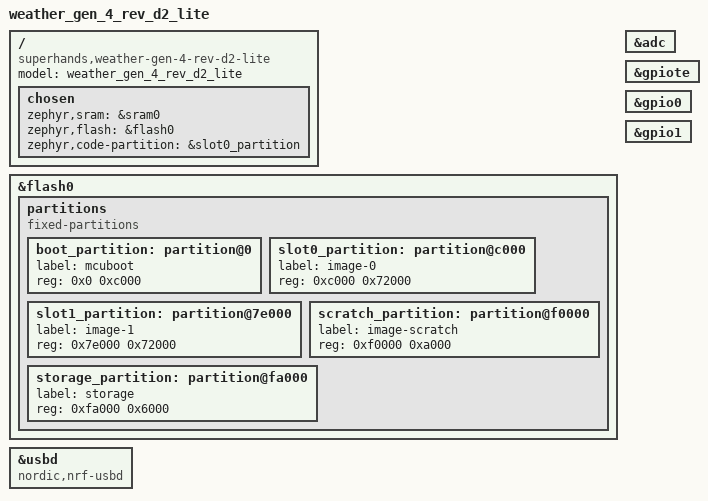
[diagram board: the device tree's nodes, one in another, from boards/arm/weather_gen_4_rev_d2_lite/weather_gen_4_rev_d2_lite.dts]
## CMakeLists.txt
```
cmake_minimum_required(VERSION 3.20.0)
find_package(Zephyr REQUIRED HINTS $ENV{ZEPHYR_BASE})

project(ble-lr-scanner)

add_subdirectory(lib/nth)

target_sources(app PRIVATE 
    src/main.cpp
    src/ble.cpp
    src/usb.cpp)
target_link_libraries(app PRIVATE nth)
target_include_directories(app PRIVATE lib/nth/inc)
```

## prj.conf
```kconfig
CONFIG_CPLUSPLUS=y
CONFIG_STD_CPP2B=y
CONFIG_LIB_CPLUSPLUS=y

CONFIG_MAIN_THREAD_PRIORITY=0
CONFIG_MAIN_STACK_SIZE=16384
CONFIG_HEAP_MEM_POOL_SIZE=8192
CONFIG_SYSTEM_WORKQUEUE_STACK_SIZE=8192
CONFIG_BT_RX_STACK_SIZE=16384
# CONFIG_LOG_PROCESS_THREAD_STACK_SIZE=16384

CONFIG_LOG=y
CONFIG_LOG_MODE_IMMEDIATE=y
CONFIG_USE_SEGGER_RTT=y
CONFIG_CONSOLE=y
CONFIG_RTT_CONSOLE=y
CONFIG_SERIAL=y
CONFIG_UART_INTERRUPT_DRIVEN=y
CONFIG_UART_LINE_CTRL=y

CONFIG_BT=y
CONFIG_BT_HCI=y
CONFIG_BT_DEBUG_LOG=y
CONFIG_BT_DEVICE_NAME="LR-Scanner"
CONFIG_BT_USER_PHY_UPDATE=y
CONFIG_BT_USER_DATA_LEN_UPDATE=y
CONFIG_BT_CTLR_PHY_CODED=y
CONFIG_BT_CTLR_DATA_LENGTH_MAX=251
CONFIG_BT_CTLR_ADV_EXT=y
# CONFIG_BT_CTLR_ADV_DATA_LEN_MAX=254
CONFIG_BT_EXT_ADV=y
CONFIG_BT_EXT_ADV_LEGACY_SUPPORT=y
CONFIG_BT_BUF_ACL_RX_SIZE=251
CONFIG_BT_BUF_ACL_TX_SIZE=251
CONFIG_BT_L2CAP_TX_MTU=247
# CONFIG_BT_MAX_CONN=2
# CONFIG_BT_MAX_PAIRED=1
# CONFIG_BT_GATT_DM=y
CONFIG_BT_GATT_CLIENT=y

# CONFIG_BT_PERIPHERAL=y
# CONFIG_BT_PERIPHERAL_PREF_MIN_INT=24
# CONFIG_BT_PERIPHERAL_PREF_MAX_INT=40
# CONFIG_BT_PERIPHERAL_PREF_LATENCY=0
# CONFIG_BT_PERIPHERAL_PREF_TIMEOUT=42
# CONFIG_BT_GAP_AUTO_UPDATE_CONN_PARAMS=n

CONFIG_BT_CENTRAL=y
CONFIG_BT_SCAN=y
CONFIG_BT_SCAN_FILTER_ENABLE=y
CONFIG_BT_SCAN_ADDRESS_CNT=1

CONFIG_REBOOT=y
CONFIG_RING_BUFFER=y
CONFIG_NEWLIB_LIBC=y
CONFIG_CBPRINTF_LIBC_SUBSTS=y
CONFIG_CBPRINTF_FP_SUPPORT=y

CONFIG_USB_DEVICE_STACK=y
CONFIG_USB_DEVICE_PRODUCT="BLE-LR Scanner"
CONFIG_USB_DEVICE_PID=0x0001
# CONFIG_USB_DEVICE_PID=0x0110
# CONFIG_USB_DEVICE_PID=0x0000
# CONFIG_USB_DEVICE_VID=0x1915
CONFIG_USB_DEVICE_INITIALIZE_AT_BOOT=n
CONFIG_USB_DEVICE_LOG_LEVEL_ERR=y
CONFIG_USB_DRIVER_LOG_LEVEL_ERR=y
CONFIG_USB_CDC_ACM=y
CONFIG_CDC_ACM_IAD=y
```

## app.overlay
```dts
/*
 * Copyright (c) 2021 Nordic Semiconductor ASA
 *
 * SPDX-License-Identifier: Apache-2.0
 */

// / {
// 	chosen {
// 		zephyr,console = &cdc_acm_uart0;
//         // zephyr,shell-uart = &cdc_acm_uart0;
// 	};
// };

&zephyr_udc0 {
	cdc_acm_uart0 {
		compatible = "zephyr,cdc-acm-uart";
	};
};
```

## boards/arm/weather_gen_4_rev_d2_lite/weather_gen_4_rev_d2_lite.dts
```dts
// Copyright (c) 2023 Nordic Semiconductor ASA
// SPDX-License-Identifier: Apache-2.0

/dts-v1/;
#include <nordic/nrf52840_qiaa.dtsi>
// #include "nrf52840dongle_nrf52840-pinctrl.dtsi"

/ {
	model = "weather_gen_4_rev_d2_lite";
	compatible = "superhands,weather-gen-4-rev-d2-lite";

	chosen {
		zephyr,sram = &sram0;
		zephyr,flash = &flash0;
		zephyr,code-partition = &slot0_partition;
		// zephyr,console = &cdc_acm_uart0;
        // zephyr,shell-uart = &cdc_acm_uart0;
	};
};

&flash0 {
	partitions {
		compatible = "fixed-partitions";
		#address-cells = <1>;
		#size-cells = <1>;

		boot_partition: partition@0 {
			label = "mcuboot";
			reg = <0x0 0xc000>;
		};
		slot0_partition: partition@c000 {
			label = "image-0";
			reg = <0xc000 0x72000>;
		};
		slot1_partition: partition@7e000 {
			label = "image-1";
			reg = <0x7e000 0x72000>;
		};
		scratch_partition: partition@f0000 {
			label = "image-scratch";
			reg = <0xf0000 0xa000>;
		};
		storage_partition: partition@fa000 {
			label = "storage";
			reg = <0xfa000 0x6000>;
		};
	};
};

&adc {
	status = "okay";
};

&gpiote {
	status = "okay";
};

&gpio0 {
	status = "okay";
};

&gpio1 {
	status = "okay";
};

// &uart0 {
// 	compatible = "nordic,nrf-uarte";
// 	status = "okay";
// 	current-speed = <115200>;
// 	// pinctrl-0 = <&uart0_default>;
// 	// pinctrl-1 = <&uart0_sleep>;
// 	// pinctrl-names = "default", "sleep";
// };

// &uart0 {
//     compatible = "zephyr,cdc-acm-uart";
//     status = "okay";
// };

zephyr_udc0: &usbd {
	compatible = "nordic,nrf-usbd";
	status = "okay";
};
```

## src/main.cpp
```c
#include <zephyr/kernel.h>
#include "ble.h"
#include "usb.h"
#include "log.h"
#include "config.h"

LOG_MODULE_REGISTER(main, LOG_LEVEL_INF);

void regout0()
{
    if ((NRF_UICR->REGOUT0 & UICR_REGOUT0_VOUT_Msk) == (UICR_REGOUT0_VOUT_DEFAULT << UICR_REGOUT0_VOUT_Pos))
    {
        NRF_NVMC->CONFIG = NVMC_CONFIG_WEN_Wen;
        while (NRF_NVMC->READY == NVMC_READY_READY_Busy) {}
        NRF_UICR->REGOUT0 = (NRF_UICR->REGOUT0 & ~((uint32_t)UICR_REGOUT0_VOUT_Msk)) | (UICR_REGOUT0_VOUT_3V0 << UICR_REGOUT0_VOUT_Pos);
        NRF_NVMC->CONFIG = NVMC_CONFIG_WEN_Ren;
        while (NRF_NVMC->READY == NVMC_READY_READY_Busy) {}
        NVIC_SystemReset();
    }
}

void approtect_hw_disable(void)
{
    if ((NRF_UICR->APPROTECT & UICR_APPROTECT_PALL_Msk) == (UICR_APPROTECT_PALL_Msk))
    {
        NRF_NVMC->CONFIG = NVMC_CONFIG_WEN_Wen << NVMC_CONFIG_WEN_Pos;
        while (NRF_NVMC->READY == NVMC_READY_READY_Busy) {}
        NRF_UICR->APPROTECT = (UICR_APPROTECT_PALL_HwDisabled << UICR_APPROTECT_PALL_Pos);
        while (NRF_NVMC->READY == NVMC_READY_READY_Busy) {}
        NRF_NVMC->CONFIG = NVMC_CONFIG_WEN_Ren << NVMC_CONFIG_WEN_Pos;
        while (NRF_NVMC->READY == NVMC_READY_READY_Busy) {}
        NVIC_SystemReset();
    }  
}

int main(void)
{
    regout0();
    approtect_hw_disable();
    app::usb_init();
#if !(USB_COBS_TEST)
    app::ble_init();
    app::ble_scan_start();
#else
    // uint8_t buf[27];
    // int cnt = 0;
    while (1) {
        // for (int i = 0; i < sizeof(buf); ++i)
        //     buf[i] = cnt * i;
        // cnt++;
        // app::usb_send(buf, sizeof(buf));
        app::usb_send("hello, world!", sizeof("hello, world!") - 1);
        app::usb_send_finalize();
        k_msleep(1000);
    }
#endif
}
```

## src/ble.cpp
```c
#include <zephyr/sys/reboot.h>
#include <zephyr/bluetooth/bluetooth.h>
#include <bluetooth/scan.h>
#include "ble.h"
#include "usb.h"
#include "log.h"
#include "config.h"

LOG_MODULE_REGISTER(ble, LOG_LEVEL_INF);

#define TRY(...)                                        \
{                                                       \
    int err = __VA_ARGS__;                              \
    if (err) {                                          \
        LOG_E("failure: " #__VA_ARGS__ " -> %d", err);  \
        return;                                         \
    }                                                   \
}

namespace app {
namespace {

struct k_work_delayable work_scan_start;
struct k_work_delayable work_scan_stop;
bool scanning = false;

constexpr auto adv_type_str(uint8_t adv_type)
{
    switch (adv_type) {
        case BT_GAP_ADV_TYPE_ADV_IND:           return "scannable and connectable";
        case BT_GAP_ADV_TYPE_ADV_DIRECT_IND:    return "directed connectable";
        case BT_GAP_ADV_TYPE_ADV_SCAN_IND:      return "non-connectable and scannable";
        case BT_GAP_ADV_TYPE_ADV_NONCONN_IND:   return "non-connectable and non-scannable";
        case BT_GAP_ADV_TYPE_SCAN_RSP:          return "additional advertising data requested by an active scanner";
        case BT_GAP_ADV_TYPE_EXT_ADV:           return "extended";
        default: return "<unknown>";
    }
}

constexpr auto phy_str(uint8_t phy)
{
    switch (phy) {
        case 0:                     return "no packets";
        case BT_GAP_LE_PHY_1M:      return "LE 1M";
        case BT_GAP_LE_PHY_2M:      return "LE 2M";
        case BT_GAP_LE_PHY_CODED:   return "LE Coded";
        default: return "<unknown>";
    }
}

void log_scan_info(struct bt_scan_device_info *info, bool connectable)
{
    char addr[BT_ADDR_LE_STR_LEN];

    bt_addr_le_to_str(info->recv_info->addr, addr, sizeof(addr));

    LOG_I("%s   \n\
        rssi:           %+d     \n\
        tx_power:       %+d     \n\
        sid:            %u      \n\
        interval:       %u ms   \n\
        adv_type:       %s      \n\
        primary_phy:    %s      \n\
        secondary_phy:  %s      \n\
        connectable:    %s",
        addr, 
        info->recv_info->rssi,
        info->recv_info->tx_power,
        info->recv_info->sid,
        info->recv_info->interval * 5 / 4,
        adv_type_str(info->recv_info->adv_type),
        phy_str(info->recv_info->primary_phy),
        phy_str(info->recv_info->secondary_phy),
        connectable ? "yes" : "no");
}

void scan_process(struct bt_scan_device_info *device_info)
{
    uint8_t* raw_data   = device_info->adv_data->data;
    uint16_t raw_len    = device_info->adv_data->len;
    LOG_HEX_D(raw_data, raw_len, "adv_data");

    usb_send(&device_info->recv_info->rssi, 1);
    usb_send(device_info->recv_info->addr->a.val, 6);
    usb_send(raw_data, raw_len);
    usb_send_finalize();

    // if (raw_len > 7) {
    //     uint8_t payload_len = raw_data[3];
    //     if (payload_len == raw_len - 4)
    //         capsule_data_check(&raw_data[5], payload_len - 1, device_info->recv_info->addr->a.val, device_info->recv_info->rssi);
    // }
}

void scan_filter_match(struct bt_scan_device_info *device_info, struct bt_scan_filter_match *filter_match, bool connectable)
{
    LOG_D(TXT_GRN "[MATCHED]");
    log_scan_info(device_info, connectable);
    scan_process(device_info);
}

void scan_filter_mismatch(struct bt_scan_device_info *device_info, bool connectable)
{
    LOG_D(TXT_RED "[NOT MATCHED]"); 
    log_scan_info(device_info, connectable);
    scan_process(device_info);
}

BT_SCAN_CB_INIT(scan_cb, scan_filter_match, scan_filter_mismatch, nullptr, nullptr);

void scan_init()
{
    // Use active scanning and disable duplicate filtering to handle any
    // devices that might update their advertising data at runtime.
    struct bt_le_scan_param scan_param = {
        .type       = BT_LE_SCAN_TYPE_PASSIVE,
#if (BLE_LONG_RANGE_SCAN)
        .options    = BT_LE_SCAN_OPT_CODED | BT_LE_SCAN_OPT_NO_1M,
#else
        .options    = BT_LE_SCAN_OPT_NONE, 
#endif
        .interval   = BT_GAP_SCAN_FAST_INTERVAL,
        .window     = 0x60, // NOTE: Seems like 0x60 is maximum.
    };

    struct bt_scan_init_param scan_init = {
        .scan_param         = &scan_param,
        .connect_if_match   = 0,
        .conn_param         = nullptr,
    };

    bt_scan_init(&scan_init);
    bt_scan_cb_register(&scan_cb);

    LOG_D("scanning initialized");
}

void scan_start(struct k_work *item)
{
    if (scanning == false) {
        scanning = true;
        TRY(bt_scan_start(BT_SCAN_TYPE_SCAN_ACTIVE));
        LOG_I("scanning started");
    } else {
        LOG_W("already started scanning");
    }
}

void scan_stop(struct k_work *item)
{
    if (scanning) {
        scanning = false;
        TRY(bt_scan_stop());
        LOG_I("scanning stopped");
    } else {
        LOG_W("already stopped scanning");
    }
}

}

void ble_init()
{
    int err = bt_enable(nullptr);
    if (err) {
        LOG_E("failure: bt_enable() -> %d", err);
        sys_reboot(SYS_REBOOT_COLD);
    } 
    scan_init();
    
    k_work_init_delayable(&work_scan_start, scan_start);
    k_work_init_delayable(&work_scan_stop, scan_stop);
}

void ble_uninit()
{
    k_work_cancel_delayable(&work_scan_start);
    k_work_cancel_delayable(&work_scan_stop);
    scan_stop(nullptr);
}

void ble_scan_start()
{
    k_work_cancel_delayable(&work_scan_start);
    scan_start(nullptr);
}

void ble_scan_stop()
{
    k_work_cancel_delayable(&work_scan_stop);
    scan_stop(nullptr);
}

}
```

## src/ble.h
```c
#ifndef BLE_H
#define BLE_H

namespace app {

void ble_init();
void ble_uninit();
void ble_scan_start();
void ble_scan_stop();

}

#endif
```

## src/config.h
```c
#ifndef CONFIG_H
#define CONFIG_H

#define USB_ECHO_TEST       false
#define USB_STATUS_CALLBACK false
#define USB_COBS            true
#define USB_COBS_TEST       false
#define BLE_LONG_RANGE_SCAN true

#endif
```

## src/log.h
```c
#ifndef LOGGER_H
#define LOGGER_H

#include <zephyr/logging/log.h>
#include <SEGGER_RTT.h>

#ifdef __cplusplus 
extern "C" {
#endif

#define TXT_CLR     RTT_CTRL_CLEAR

#define TXT_RED     RTT_CTRL_TEXT_BRIGHT_RED
#define TXT_CYN     RTT_CTRL_TEXT_BRIGHT_CYAN
#define TXT_BLU     RTT_CTRL_TEXT_BRIGHT_BLUE
#define TXT_GRN     RTT_CTRL_TEXT_BRIGHT_GREEN
#define TXT_WHT     RTT_CTRL_TEXT_BRIGHT_WHITE
#define TXT_YEL     RTT_CTRL_TEXT_BRIGHT_YELLOW
#define TXT_MAG     RTT_CTRL_TEXT_BRIGHT_MAGENTA

#define LOG_I(fmt, ...)     LOG_INF(TXT_CYN fmt, ##__VA_ARGS__)
#define LOG_D(fmt, ...)     LOG_DBG(TXT_BLU fmt, ##__VA_ARGS__)
#define LOG_W(fmt, ...)     LOG_WRN(fmt, ##__VA_ARGS__)
#define LOG_E(fmt, ...)     LOG_ERR(fmt, ##__VA_ARGS__)

#define LOG_GRN(fmt, ...)   LOG_INF(TXT_GRN fmt, ##__VA_ARGS__)
#define LOG_RED(fmt, ...)   LOG_INF(TXT_RED fmt, ##__VA_ARGS__)

#define LOG_HEX_I(data, len, str)   LOG_HEXDUMP_INF(data, len, TXT_CYN str)
#define LOG_HEX_D(data, len, str)   LOG_HEXDUMP_DBG(data, len, TXT_BLU str)
#define LOG_HEX_W(data, len, str)   LOG_HEXDUMP_WRN(data, len, str)
#define LOG_HEX_E(data, len, str)   LOG_HEXDUMP_ERR(data, len, str)

#ifdef __cplusplus 
}
#endif

#endif
```

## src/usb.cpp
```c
#include <zephyr/usb/usb_device.h>
#include <zephyr/usb/usbd.h>
#include <zephyr/drivers/uart.h>
#include <zephyr/sys/ring_buffer.h>
#include "usb.h"
#include "log.h"
#include "config.h"
#if (USB_COBS)
#include <nth/nth.h>
#endif

LOG_MODULE_REGISTER(usb, LOG_LEVEL_DBG);

namespace app {
namespace {

#if (USB_ECHO_TEST)
constexpr auto ring_buf_size = 1024;

uint8_t ring_buffer[ring_buf_size];
struct ring_buf ringbuf;
#endif
const struct device* dev;
#if (USB_COBS)
nth::cobs_pipe_encoder cobs_pipe;
#endif

#if (USB_ECHO_TEST)

void interrupt_handler(const struct device *dev, void *user_data)
{
	ARG_UNUSED(user_data);

    while (uart_irq_update(dev) && uart_irq_is_pending(dev)) {

        if (uart_irq_rx_ready(dev)) {

            int recv_len;
            int rb_len;
            uint8_t buffer[64];
            size_t len = MIN(ring_buf_space_get(&ringbuf), sizeof(buffer));
            recv_len = uart_fifo_read(dev, buffer, len);

            if (recv_len < 0) {
                recv_len = 0;
                LOG_E("Failed to read UART FIFO");
            }
            rb_len = ring_buf_put(&ringbuf, buffer, recv_len);

            if (rb_len < recv_len)
                LOG_E("Drop %u bytes", recv_len - rb_len);

            LOG_D("tty fifo -> ringbuf %d bytes", rb_len);

            if (rb_len)
                uart_irq_tx_enable(dev);
        }

        if (uart_irq_tx_ready(dev)) {

            uint8_t buffer[64];

            int rb_len = ring_buf_get(&ringbuf, buffer, sizeof(buffer));
            if (!rb_len) {
                LOG_D("Ring buffer empty, disable TX IRQ");
                uart_irq_tx_disable(dev);
                continue;
            }
            int send_len = uart_fifo_fill(dev, buffer, rb_len);
            if (send_len < rb_len) 
                LOG_E("Drop %d bytes", rb_len - send_len);

            LOG_D("ringbuf -> tty fifo %d bytes", send_len);
		}
	}
}

#endif

#if (USB_STATUS_CALLBACK)

void usb_status_handler(enum usb_dc_status_code cb_status, const uint8_t* param)
{

}

#endif

#if (USB_COBS)

size_t cobs_write_handler(const uint8_t* data, size_t size)
{
    LOG_HEX_I(data, size, TXT_MAG "USB TX COBS chunk");
    return size_t(uart_fifo_fill(dev, data, size));
}

#endif

}

void usb_init()
{
#if (USB_ECHO_TEST)
    ring_buf_init(&ringbuf, sizeof(ring_buffer), ring_buffer);
#endif
    dev = DEVICE_DT_GET_ONE(zephyr_cdc_acm_uart);

    if (!device_is_ready(dev)) {
        LOG_E("failure: CDC ACM device not ready");
        return;
    }
#if (USB_STATUS_CALLBACK)
    int ret = usb_enable(usb_status_handler);
#else
    int ret = usb_enable(nullptr);
#endif
    if (ret != 0) {
        LOG_E("failure: usb_enable() -> %d", ret);
        return;
    }
#if (USB_ECHO_TEST)

    LOG_I("Wait for DTR");

    uint32_t dtr = 0;

    while (true) {
        uart_line_ctrl_get(dev, UART_LINE_CTRL_DTR, &dtr);
        if (dtr)
            break;
        else
            k_msleep(100); /* Give CPU resources to low priority threads. */
    }
    LOG_I("DTR set");

    /* They are optional, we use them to test the interrupt endpoint */
    ret = uart_line_ctrl_set(dev, UART_LINE_CTRL_DCD, 1);
    if (ret)
        LOG_W("failure: set DCD, uart_line_ctrl_set() -> %d", ret);

    ret = uart_line_ctrl_set(dev, UART_LINE_CTRL_DSR, 1);
    if (ret)
        LOG_W("failure: set DSR, uart_line_ctrl_set() -> %d", ret);

    k_msleep(1000); // Wait 1 sec for the host to do all settings

    uint32_t baudrate = 0;

    ret = uart_line_ctrl_get(dev, UART_LINE_CTRL_BAUD_RATE, &baudrate);
    if (ret)
        LOG_W("failure: get baudrate, uart_line_ctrl_get() -> %d", ret);
    else
        LOG_I("baudrate: %d", baudrate);

    uart_irq_callback_set(dev, interrupt_handler);
	uart_irq_rx_enable(dev);
#endif
}

bool usb_send(const void* data, size_t size)
{
    LOG_HEX_I(data, size, "USB TX raw chunk");
#if (USB_COBS)
    cobs_pipe.sink({static_cast<const uint8_t*>(data), size}, cobs_write_handler);
    return true;
#else
    uint8_t len = size;
    return  uart_fifo_fill(dev, &len, 1) == 1 &&
            uart_fifo_fill(dev, data, size) == int(size);
#endif
}

bool usb_send_finalize()
{
#if (USB_COBS)
    cobs_pipe.stop(cobs_write_handler);
    return true;
#else
    static_assert(false);
#endif
}

}
```

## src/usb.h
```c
#ifndef USB_H
#define USB_H

#include <cstdint>
#include <cstddef>

namespace app {

void usb_init();
bool usb_send(const void* data, size_t size);
bool usb_send_finalize();

}

#endif
```
